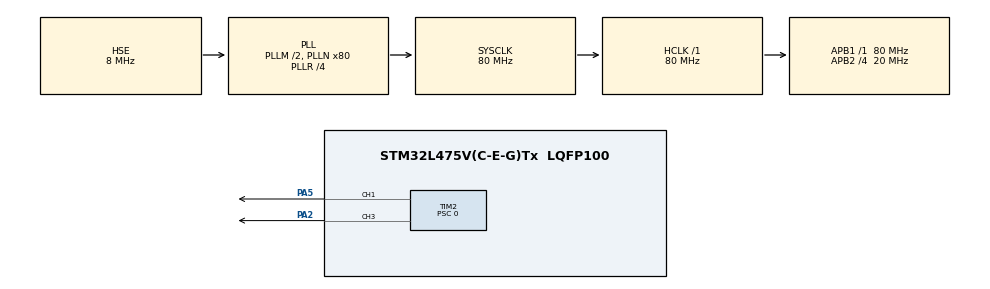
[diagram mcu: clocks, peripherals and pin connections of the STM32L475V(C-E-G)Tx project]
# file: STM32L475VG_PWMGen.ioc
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Mcu.Family=STM32L4
Mcu.Name=STM32L475V(C-E-G)Tx
Mcu.Package=LQFP100
NVIC.PriorityGroup=NVIC_PRIORITYGROUP_4
NVIC.TIM2_IRQn=true\:0\:0\:false\:false\:true\:true\:true
PA2.Signal=S_TIM2_CH3
PA5.Signal=S_TIM2_CH1
PB14.Signal=TIM1_CH2N
PH0-OSC_IN\ (PH0).Mode=HSE-External-Oscillator
PH0-OSC_IN\ (PH0).Signal=RCC_OSC_IN
PH1-OSC_OUT\ (PH1).Mode=HSE-External-Oscillator
PH1-OSC_OUT\ (PH1).Signal=RCC_OSC_OUT
ProjectManager.HeapSize=0x200
ProjectManager.StackSize=0x400
ProjectManager.TargetToolchain=STM32CubeIDE
RCC.ADCFreq_Value=16000000
RCC.AHBFreq_Value=80000000
RCC.APB1Freq_Value=80000000
RCC.APB1TimFreq_Value=80000000
RCC.APB2CLKDivider=RCC_HCLK_DIV4
RCC.APB2Freq_Value=20000000
RCC.APB2TimFreq_Value=40000000
RCC.CortexFreq_Value=80000000
RCC.HCLKFreq_Value=80000000
RCC.HSE_VALUE=8000000
RCC.HSI_VALUE=16000000
RCC.LSE_VALUE=32768
RCC.MSI_VALUE=4000000
RCC.PLLM=2
RCC.PLLN=80
RCC.PLLR=RCC_PLLR_DIV4
RCC.PLLSourceVirtual=RCC_PLLSOURCE_HSE
RCC.SYSCLKFreq_VALUE=80000000
RCC.SYSCLKSource=RCC_SYSCLKSOURCE_PLLCLK
RCC.USBFreq_Value=16000000
RCC.VCOOutputFreq_Value=320000000
SH.S_TIM2_CH1.0=TIM2_CH1,PWM Generation1 CH1
SH.S_TIM2_CH3.0=TIM2_CH3,PWM Generation3 CH3
TIM2.Channel-PWM\ Generation1\ CH1=TIM_CHANNEL_1
TIM2.Channel-PWM\ Generation3\ CH3=TIM_CHANNEL_3
TIM2.ClockDivision=TIM_CLOCKDIVISION_DIV1
TIM2.Period=80000 -1 
TIM2.Prescaler=0
VP_TIM2_VS_ClockSourceINT.Mode=Internal
board=custom

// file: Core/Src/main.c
/* USER CODE BEGIN Header */
/**
  ******************************************************************************
  * @file           : main.c
  * @brief          : Main program body
  ******************************************************************************
  * @attention
  *
  * <h2><center>&copy; Copyright (c) 2020 STMicroelectronics.
  * All rights reserved.</center></h2>
  *
  * This software component is licensed by ST under BSD 3-Clause license,
  * the "License"; You may not use this file except in compliance with the
  * License. You may obtain a copy of the License at:
  *                        opensource.org/licenses/BSD-3-Clause
  *
  ******************************************************************************
  */
/* USER CODE END Header */
#include "main.h"

TIM_HandleTypeDef htim2;

void SystemClock_Config(void);
static void MX_GPIO_Init(void);
static void MX_TIM2_Init(void);

/* USER CODE BEGIN 0 */
//set value for led
void set_led(uint32_t lght)
{
	htim2.Instance->CCR1 = lght; //LED
	htim2.Instance->CCR3 = lght; //Servo MOto
}
/* USER CODE END 0 */

int main(void)
{

  /* MCU Configuration--------------------------------------------------------*/

  /* Reset of all peripherals, Initializes the Flash interface and the Systick. */
  HAL_Init();

  /* Configure the system clock */
  SystemClock_Config();

  /* Initialize all configured peripherals */
  MX_GPIO_Init();
  MX_TIM2_Init();
  /* USER CODE BEGIN 2 */
  HAL_TIM_PWM_Start(&htim2,TIM_CHANNEL_1);
  HAL_TIM_PWM_Start(&htim2,TIM_CHANNEL_3);
  int i = 1000;
  /* USER CODE END 2 */

  /* Infinite loop */
  while (1)
  {

    /* USER CODE BEGIN 3 */

	  	 //HAL_Delay(250);//Delay
	  	 while(i<10000)
	  	 {
	  		 set_led(i);
	  		 i=i+50;
	  		 HAL_Delay(10);//Delay
	  	 }
	  	while(i>=1000)
			 {
				 set_led(i);
				 i=i-50;
				 HAL_Delay(10);//Delay
			 }
	  	i = 1000;
  }
  /* USER CODE END 3 */
}

void SystemClock_Config(void)
{
  RCC_OscInitTypeDef RCC_OscInitStruct = {0};
  RCC_ClkInitTypeDef RCC_ClkInitStruct = {0};

  /** Initializes the RCC Oscillators according to the specified parameters
  * in the RCC_OscInitTypeDef structure.
  */
  RCC_OscInitStruct.OscillatorType = RCC_OSCILLATORTYPE_HSE;
  RCC_OscInitStruct.HSEState = RCC_HSE_ON;
  RCC_OscInitStruct.PLL.PLLState = RCC_PLL_ON;
  RCC_OscInitStruct.PLL.PLLSource = RCC_PLLSOURCE_HSE;
  RCC_OscInitStruct.PLL.PLLM = 2;
  RCC_OscInitStruct.PLL.PLLN = 80;
  RCC_OscInitStruct.PLL.PLLP = RCC_PLLP_DIV7;
  RCC_OscInitStruct.PLL.PLLQ = RCC_PLLQ_DIV2;
  RCC_OscInitStruct.PLL.PLLR = RCC_PLLR_DIV4;
  if (HAL_RCC_OscConfig(&RCC_OscInitStruct) != HAL_OK)
  {
    Error_Handler();
  }
  /** Initializes the CPU, AHB and APB buses clocks
  */
  RCC_ClkInitStruct.ClockType = RCC_CLOCKTYPE_HCLK|RCC_CLOCKTYPE_SYSCLK
                              |RCC_CLOCKTYPE_PCLK1|RCC_CLOCKTYPE_PCLK2;
  RCC_ClkInitStruct.SYSCLKSource = RCC_SYSCLKSOURCE_PLLCLK;
  RCC_ClkInitStruct.AHBCLKDivider = RCC_SYSCLK_DIV1;
  RCC_ClkInitStruct.APB1CLKDivider = RCC_HCLK_DIV1;
  RCC_ClkInitStruct.APB2CLKDivider = RCC_HCLK_DIV4;

  if (HAL_RCC_ClockConfig(&RCC_ClkInitStruct, FLASH_LATENCY_4) != HAL_OK)
  {
    Error_Handler();
  }
  /** Configure the main internal regulator output voltage
  */
  if (HAL_PWREx_ControlVoltageScaling(PWR_REGULATOR_VOLTAGE_SCALE1) != HAL_OK)
  {
    Error_Handler();
  }
}

static void MX_TIM2_Init(void)
{

  TIM_ClockConfigTypeDef sClockSourceConfig = {0};
  TIM_MasterConfigTypeDef sMasterConfig = {0};
  TIM_OC_InitTypeDef sConfigOC = {0};

  htim2.Instance = TIM2;
  htim2.Init.Prescaler = 0;
  htim2.Init.CounterMode = TIM_COUNTERMODE_UP;
  htim2.Init.Period = 80000 -1 ;
  htim2.Init.ClockDivision = TIM_CLOCKDIVISION_DIV1;
  htim2.Init.AutoReloadPreload = TIM_AUTORELOAD_PRELOAD_DISABLE;
  if (HAL_TIM_Base_Init(&htim2) != HAL_OK)
  {
    Error_Handler();
  }
  sClockSourceConfig.ClockSource = TIM_CLOCKSOURCE_INTERNAL;
  if (HAL_TIM_ConfigClockSource(&htim2, &sClockSourceConfig) != HAL_OK)
  {
    Error_Handler();
  }
  if (HAL_TIM_PWM_Init(&htim2) != HAL_OK)
  {
    Error_Handler();
  }
  sMasterConfig.MasterOutputTrigger = TIM_TRGO_RESET;
  sMasterConfig.MasterSlaveMode = TIM_MASTERSLAVEMODE_DISABLE;
  if (HAL_TIMEx_MasterConfigSynchronization(&htim2, &sMasterConfig) != HAL_OK)
  {
    Error_Handler();
  }
  sConfigOC.OCMode = TIM_OCMODE_PWM1;
  sConfigOC.Pulse = 0;
  sConfigOC.OCPolarity = TIM_OCPOLARITY_HIGH;
  sConfigOC.OCFastMode = TIM_OCFAST_DISABLE;
  if (HAL_TIM_PWM_ConfigChannel(&htim2, &sConfigOC, TIM_CHANNEL_1) != HAL_OK)
  {
    Error_Handler();
  }
  if (HAL_TIM_PWM_ConfigChannel(&htim2, &sConfigOC, TIM_CHANNEL_3) != HAL_OK)
  {
    Error_Handler();
  }
  HAL_TIM_MspPostInit(&htim2);

}

static void MX_GPIO_Init(void)
{
  GPIO_InitTypeDef GPIO_InitStruct = {0};

  /* GPIO Ports Clock Enable */
  __HAL_RCC_GPIOH_CLK_ENABLE();
  __HAL_RCC_GPIOA_CLK_ENABLE();
  __HAL_RCC_GPIOB_CLK_ENABLE();

  /*Configure GPIO pin : PB14 */
  GPIO_InitStruct.Pin = GPIO_PIN_14;
  GPIO_InitStruct.Mode = GPIO_MODE_AF_PP;
  GPIO_InitStruct.Pull = GPIO_NOPULL;
  GPIO_InitStruct.Speed = GPIO_SPEED_FREQ_LOW;
  GPIO_InitStruct.Alternate = GPIO_AF1_TIM1;
  HAL_GPIO_Init(GPIOB, &GPIO_InitStruct);

}

void Error_Handler(void)
{
}

/************************ (C) COPYRIGHT STMicroelectronics *****END OF FILE****/
